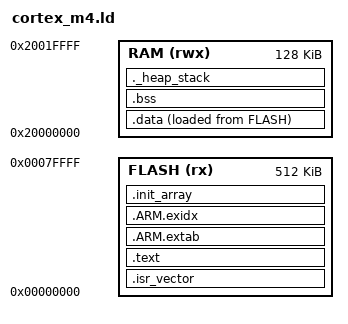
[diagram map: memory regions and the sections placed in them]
/*
 * Minimal linker script for a generic Cortex-M4F: 512 KiB flash at 0x0,
 * 128 KiB SRAM at 0x20000000. It exists so the cortex-m4 profile links a
 * complete image; it does not describe a real part.
 */
ENTRY(Reset_Handler)

MEMORY
{
    FLASH (rx)  : ORIGIN = 0x00000000, LENGTH = 512K
    RAM   (rwx) : ORIGIN = 0x20000000, LENGTH = 128K
}

_estack = ORIGIN(RAM) + LENGTH(RAM);
_min_heap_size = 0x1000;
_min_stack_size = 0x1000;

SECTIONS
{
    .isr_vector :
    {
        . = ALIGN(4);
        KEEP(*(.isr_vector))
        . = ALIGN(4);
    } > FLASH

    .text :
    {
        . = ALIGN(4);
        *(.text .text.*)
        *(.rodata .rodata.*)
        KEEP(*(.init))
        KEEP(*(.fini))
        . = ALIGN(4);
    } > FLASH

    .ARM.extab : { *(.ARM.extab* .gnu.linkonce.armextab.*) } > FLASH
    .ARM.exidx :
    {
        __exidx_start = .;
        *(.ARM.exidx* .gnu.linkonce.armexidx.*)
        __exidx_end = .;
    } > FLASH

    .init_array :
    {
        . = ALIGN(4);
        PROVIDE_HIDDEN(__preinit_array_start = .);
        KEEP(*(.preinit_array*))
        PROVIDE_HIDDEN(__preinit_array_end = .);
        PROVIDE_HIDDEN(__init_array_start = .);
        KEEP(*(SORT(.init_array.*)))
        KEEP(*(.init_array*))
        PROVIDE_HIDDEN(__init_array_end = .);
        PROVIDE_HIDDEN(__fini_array_start = .);
        KEEP(*(SORT(.fini_array.*)))
        KEEP(*(.fini_array*))
        PROVIDE_HIDDEN(__fini_array_end = .);
        . = ALIGN(4);
    } > FLASH

    /* Initial values live in flash; Reset_Handler copies them to RAM. */
    _sidata = LOADADDR(.data);
    .data :
    {
        . = ALIGN(4);
        _sdata = .;
        *(.data .data.*)
        . = ALIGN(4);
        _edata = .;
    } > RAM AT > FLASH

    .bss (NOLOAD) :
    {
        . = ALIGN(4);
        _sbss = .;
        *(.bss .bss.*)
        *(COMMON)
        . = ALIGN(4);
        _ebss = .;
    } > RAM

    /* Fails the link if the heap and stack minimums no longer fit in RAM. */
    ._heap_stack (NOLOAD) :
    {
        . = ALIGN(8);
        PROVIDE(end = .);
        PROVIDE(_end = .);
        . = . + _min_heap_size;
        . = . + _min_stack_size;
        . = ALIGN(8);
    } > RAM

    .ARM.attributes 0 : { *(.ARM.attributes) }
}
